# ATSAMA5D27CLD1G device description
Architecture: CORTEX-A5; Family: SAMA5; Series: SAMA5D2
Registers are 32-bit, read-write, no defined reset value unless marked. A register's access mark holds for its fields unless they carry their own. Offsets are from the block's base; [hi:lo] are bit positions; {n}, {i} and the like mark numbered series.

## SFC — Secure Fuse Controller
Instances: SFC 0xF804C000
0x00 SFC_KR wo — SFC Key Register
  [7:0] KEY — Key Code
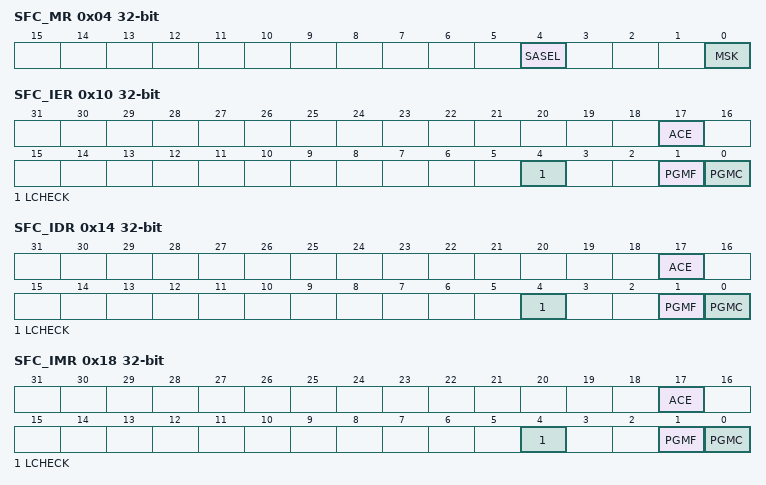
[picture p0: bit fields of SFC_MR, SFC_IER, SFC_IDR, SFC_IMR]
0x04 SFC_MR — SFC Mode Register
  [4] SASEL — Sense Amplifier Selection
  [0] MSK — Mask Data Registers
0x10 SFC_IER wo — SFC Interrupt Enable Register
  [17] ACE — Area Check Error Interrupt Enable
  [4] LCHECK — Live Integrity Check Error Interrupt Enable
  [1] PGMF — Programming Sequence Failed Interrupt Enable
  [0] PGMC — Programming Sequence Completed Interrupt Enable
0x14 SFC_IDR wo — SFC Interrupt Disable Register
  [17] ACE — Area Check Error Interrupt Disable
  [4] LCHECK — Live Integrity Check Error Interrupt Disable
  [1] PGMF — Programming Sequence Failed Interrupt Disable
  [0] PGMC — Programming Sequence Completed Interrupt Disable
0x18 SFC_IMR ro — SFC Interrupt Mask Register
  [17] ACE — Area Check Error Interrupt Mask
  [4] LCHECK — Live Integrity Checking Error Interrupt Mask
  [1] PGMF — Programming Sequence Failed Interrupt Mask
  [0] PGMC — Programming Sequence Completed Interrupt Mask
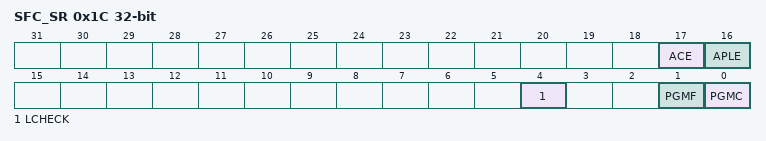
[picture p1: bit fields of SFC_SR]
0x1C SFC_SR ro — SFC Status Register
  [17] ACE — Area Check Error (cleared on read)
  [16] APLE — Area Programming Lock Error (cleared on read)
  [4] LCHECK — Live Integrity Checking Error (cleared on read)
  [1] PGMF — Programming Sequence Failed (cleared on read)
  [0] PGMC — Programming Sequence Completed (cleared on read)
{0x20+4i} SFC_DR[{i}] (i=0..16) — SFC Data Register
  [31:0] DATA — Fuse Data

## SFR — Special Function Registers
Instances: SFR 0xF8030000
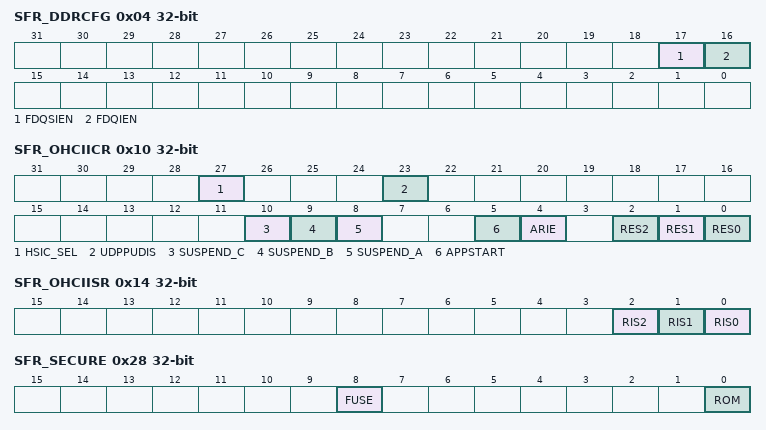
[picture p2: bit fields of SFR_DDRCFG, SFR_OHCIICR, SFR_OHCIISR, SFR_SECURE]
0x04 SFR_DDRCFG — DDR Configuration Register
  [17] FDQSIEN — Force DDR_DQS Input Buffer Always On
  [16] FDQIEN — Force DDR_DQ Input Buffer Always On
0x10 SFR_OHCIICR — OHCI Interrupt Configuration Register
  [27] HSIC_SEL — Reserved
  [23] UDPPUDIS — USB DEVICE PULLUP DISABLE
  [10] SUSPEND_C — USB PORT C
  [9] SUSPEND_B — USB PORT B
  [8] SUSPEND_A — USB PORT A
  [5] APPSTART — Reserved
  [4] ARIE — OHCI Asynchronous Resume Interrupt Enable
  [2] RES2 — USB PORTx RESET
  [1] RES1 — USB PORTx RESET
  [0] RES0 — USB PORTx RESET
0x14 SFR_OHCIISR ro — OHCI Interrupt Status Register
  [2] RIS2 — OHCI Resume Interrupt Status Port 2
  [1] RIS1 — OHCI Resume Interrupt Status Port 1
  [0] RIS0 — OHCI Resume Interrupt Status Port 0
0x28 SFR_SECURE — Security Configuration Register
  [8] FUSE — Disable Access to Fuse Controller
  [0] ROM — Disable Access to ROM Code
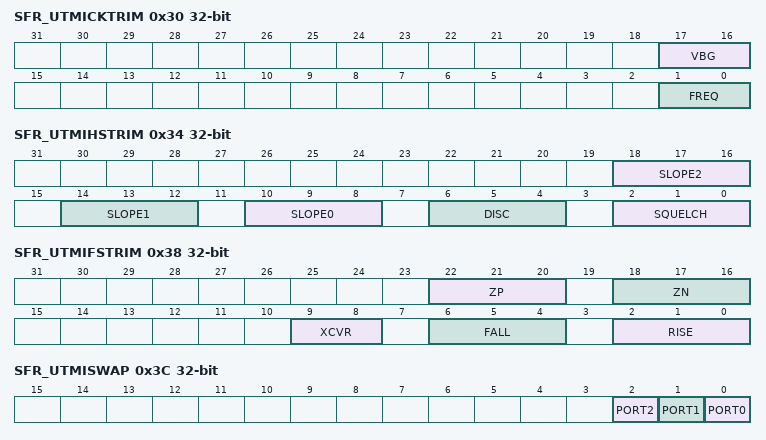
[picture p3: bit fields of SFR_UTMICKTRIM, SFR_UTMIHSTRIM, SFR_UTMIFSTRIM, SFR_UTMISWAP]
0x30 SFR_UTMICKTRIM — UTMI Clock Trimming Register
  [17:16] VBG — UTMI Band Gap Voltage Trimming
  [1:0] FREQ — UTMI Reference Clock Frequency
    0=12 MHz reference clock; 1=16 MHz reference clock; 2=24 MHz reference clock
0x34 SFR_UTMIHSTRIM — UTMI High-Speed Trimming Register
  [18:16] SLOPE2 — UTMI HS PORTx Transceiver Slope Trimming
  [14:12] SLOPE1 — UTMI HS PORTx Transceiver Slope Trimming
  [10:8] SLOPE0 — UTMI HS PORTx Transceiver Slope Trimming
  [6:4] DISC — UTMI Disconnect Voltage Trimming
  [2:0] SQUELCH — UTMI HS SQUELCH Voltage Trimming
0x38 SFR_UTMIFSTRIM — UTMI Full-Speed Trimming Register
  [22:20] ZP — FS Transceiver PMOS Impedance Trimming
  [18:16] ZN — FS Transceiver NMOS Impedance Trimming
  [9:8] XCVR — FS Transceiver Crossover Voltage Trimming
  [6:4] FALL — FS Transceiver Output Falling Slope Trimming
  [2:0] RISE — FS Transceiver Output Rising Slope Trimming
0x3C SFR_UTMISWAP — UTMI DP/DM Pin Swapping Register
  [all] fields
    0=NORMAL (DP/DM normal pinout.); 1=SWAPPED (DP/DM swapped pinout.)
  [2] PORT2 — PORT 2 DP/DM Pin Swapping
  [1] PORT1 — PORT 1 DP/DM Pin Swapping
  [0] PORT0 — PORT 0 DP/DM Pin Swapping
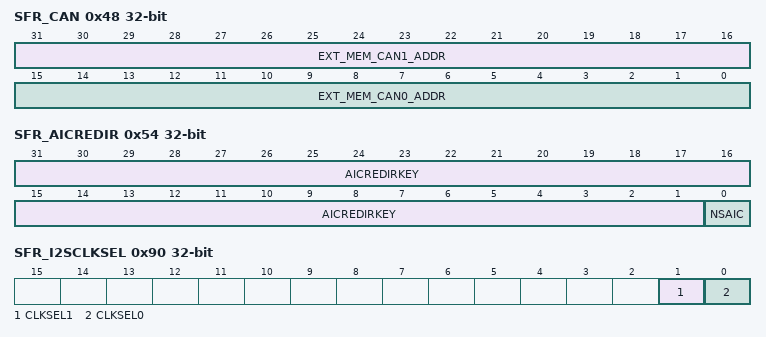
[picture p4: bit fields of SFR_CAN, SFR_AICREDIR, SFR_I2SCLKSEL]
0x48 SFR_CAN — CAN Memories Address-based Register
  [31:16] EXT_MEM_CAN1_ADDR — MSB CAN1 DMA Base Address
  [15:0] EXT_MEM_CAN0_ADDR — MSB CAN0 DMA Base Address
0x4C SFR_SN0 ro — Serial Number 0 Register
  [31:0] SN0 — Serial Number 0
0x50 SFR_SN1 ro — Serial Number 1 Register
  [31:0] SN1 — Serial Number 1
0x54 SFR_AICREDIR — AIC Interrupt Redirection Register
  [31:1] AICREDIRKEY — Unlock Key
  [0] NSAIC — Interrupt Redirection to Non-Secure AIC
0x58 SFR_L2CC_HRAMC — L2CC_HRAMC1
  [0] SRAM_SEL — SRAM Selector
0x90 SFR_I2SCLKSEL — I2SC Register
  [1] CLKSEL1 — Clock Selection 1
  [0] CLKSEL0 — Clock Selection 0
0x94 QSPICLK_REG — QSPI Clock Pad Supply Select Register
  [0] SUP_SEL — Supply Selection

## Notices in the file
Copyright 2020 Microchip Technology Inc.
SPDX-License-Identifier: Apache-2.0
Licensed under the Apache License, Version 2.0 (the "License");
you may not use this file except in compliance with the License.
You may obtain a copy of the License at
http://www.apache.org/licenses/LICENSE-2.0
Unless required by applicable law or agreed to in writing, software
distributed under the License is distributed on an "AS IS" BASIS,
WITHOUT WARRANTIES OR CONDITIONS OF ANY KIND, either express or implied.
See the License for the specific language governing permissions and
limitations under the License.
